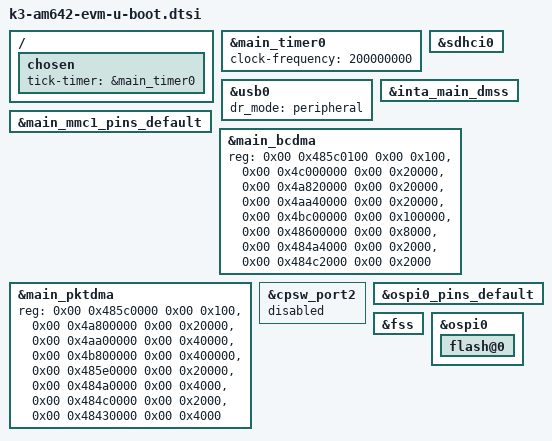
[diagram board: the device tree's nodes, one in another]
// SPDX-License-Identifier: GPL-2.0
/*
 * Copyright (C) 2020-2021 Texas Instruments Incorporated - https://www.ti.com/
 */

#include "k3-am64x-binman.dtsi"

/ {
	chosen {
		tick-timer = &main_timer0;
	};
};

&main_timer0 {
	clock-frequency = <200000000>;
};

&usb0 {
	dr_mode="peripheral";
};

&main_mmc1_pins_default {
	bootph-all;
};

&sdhci0 {
	bootph-all;
};

&main_mmc1_pins_default {
	bootph-all;
};

&inta_main_dmss {
	bootph-all;
};

&main_bcdma {
	reg = <0x00 0x485c0100 0x00 0x100>,
	      <0x00 0x4c000000 0x00 0x20000>,
	      <0x00 0x4a820000 0x00 0x20000>,
	      <0x00 0x4aa40000 0x00 0x20000>,
	      <0x00 0x4bc00000 0x00 0x100000>,
	      <0x00 0x48600000 0x00 0x8000>,
	      <0x00 0x484a4000 0x00 0x2000>,
	      <0x00 0x484c2000 0x00 0x2000>;
	reg-names = "gcfg", "bchanrt", "rchanrt", "tchanrt", "ringrt",
		    "cfg", "tchan", "rchan";
};

&main_pktdma {
	reg = <0x00 0x485c0000 0x00 0x100>,
	      <0x00 0x4a800000 0x00 0x20000>,
	      <0x00 0x4aa00000 0x00 0x40000>,
	      <0x00 0x4b800000 0x00 0x400000>,
	      <0x00 0x485e0000 0x00 0x20000>,
	      <0x00 0x484a0000 0x00 0x4000>,
	      <0x00 0x484c0000 0x00 0x2000>,
	      <0x00 0x48430000 0x00 0x4000>;
	reg-names = "gcfg", "rchanrt", "tchanrt", "ringrt", "cfg",
		    "tchan", "rchan", "rflow";
	bootph-all;
};

&cpsw_port2 {
	status = "disabled";
};

&ospi0_pins_default {
	bootph-all;
};

&fss {
	bootph-all;
};

&ospi0 {
	bootph-all;

	flash@0 {
		bootph-all;
	};
};
